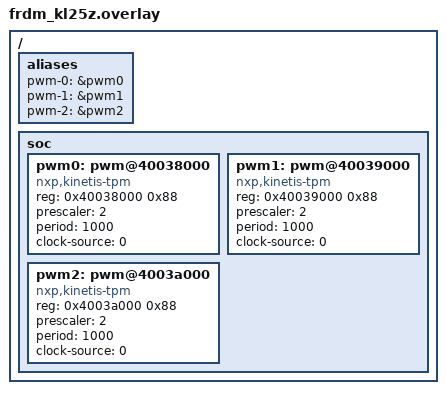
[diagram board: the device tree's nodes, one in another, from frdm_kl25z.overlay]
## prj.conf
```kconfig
CONFIG_STDOUT_CONSOLE=y
CONFIG_LOG=y
# CONFIG_SYS_CLOCK_TICKS_PER_SEC=250
#CONFIG_MICROBIT_DISPLAY_PIN_GRANULARITY=y

# PWM
# CONFIG_PWM=y
# CONFIG_PWM_0=y

# USB
# CONFIG_STDOUT_CONSOLE=y
# CONFIG_GPIO=y
# CONFIG_USB=y
# CONFIG_USB_DEVICE_STACK=y
# CONFIG_USB_DEVICE_BOS=y
# CONFIG_SERIAL=y
# CONFIG_USB_DEVICE_PRODUCT="Zephyr WebUSB sample"
# CONFIG_UART_INTERRUPT_DRIVEN=y
# CONFIG_UART_LINE_CTRL=y

# CONFIG_LOG=y
# CONFIG_USB_DRIVER_LOG_LEVEL_ERR=y
# CONFIG_USB_DEVICE_LOG_LEVEL_ERR=y

#CONFIG_USB_DEVICE_VID=
#CONFIG_USB_DEVICE_PID=

CONFIG_I2C=y
CONFIG_SENSOR=y
CONFIG_FXOS8700=y
CONFIG_SENSOR_LOG_LEVEL_DBG=y
# CONFIG_FXOS8700_MODE_HYBRID=y
# CONFIG_FXOS8700_TEMP=y
CONFIG_FXOS8700_TRIGGER_OWN_THREAD=y
```

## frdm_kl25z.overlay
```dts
/ {
	aliases {
		pwm-0 = &pwm0;
		pwm-1 = &pwm1;
		pwm-2 = &pwm2;
	};

	soc {
		pwm0: pwm@40038000 {
			compatible = "nxp,kinetis-tpm";
			reg = <0x40038000 0x88>;
			prescaler = <2>;
			period = <1000>;
			clock-source = <0>;
			/* channel information needed - fixme */
		};

		pwm1: pwm@40039000 {
			compatible = "nxp,kinetis-tpm";
			reg = <0x40039000 0x88>;
			prescaler = <2>;
			period = <1000>;
			clock-source = <0>;
			/* channel information needed - fixme */
		};

		pwm2: pwm@4003a000 {
			compatible = "nxp,kinetis-tpm";
			reg = <0x4003a000 0x88>;
			prescaler = <2>;
			period = <1000>;
			clock-source = <0>;
			/* channel information needed - fixme */
		};
	};
};
```

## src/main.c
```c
#include <zephyr.h>
#include <sensor.h>
#include <stdio.h>

#include "rgb_led.h"

K_SEM_DEFINE(sem, 0, 1);	/* starts off "not available" */

static void trigger_handler(struct device *dev, struct sensor_trigger *trigger)
{
	ARG_UNUSED(trigger);

	if (sensor_sample_fetch(dev)) {
		printf("sensor_sample_fetch failed\n");
		return;
	}

	k_sem_give(&sem);
}

void main(void)
{
	struct sensor_value accel[3];
	struct device *dev = device_get_binding(DT_NXP_FXOS8700_0_LABEL);

	if (dev == NULL) {
		printf("Could not get fxos8700 device\n");
		return;
	}

	struct sensor_value attr = {
		.val1 = 6,
		.val2 = 250000,
	};

	// if (val->val1 == 800 && val->val2 == 0) {
	// 	dr = FXOS8700_CTRLREG1_DR_RATE_800;
	// } else if (val->val1 == 400 && val->val2 == 0) {
	// 	dr = FXOS8700_CTRLREG1_DR_RATE_400;
	// } else if (val->val1 == 200 && val->val2 == 0) {
	// 	dr = FXOS8700_CTRLREG1_DR_RATE_200;
	// } else if (val->val1 == 100 && val->val2 == 0) {
	// 	dr = FXOS8700_CTRLREG1_DR_RATE_100;
	// } else if (val->val1 == 50 && val->val2 == 0) {
	// 	dr = FXOS8700_CTRLREG1_DR_RATE_50;
	// } else if (val->val1 == 12 && val->val2 == 500000) {
	// 	dr = FXOS8700_CTRLREG1_DR_RATE_12_5;
	// } else if (val->val1 == 6 && val->val2 == 250000) {
	// 	dr = FXOS8700_CTRLREG1_DR_RATE_6_25;
	// } else if (val->val1 == 1 && val->val2 == 562500) {
	// 	dr = FXOS8700_CTRLREG1_DR_RATE_1_56;
	// } else {
	// 	return -EINVAL;
	// }

	if (sensor_attr_set(dev, SENSOR_CHAN_ALL,
			    SENSOR_ATTR_SAMPLING_FREQUENCY, &attr)) {
		printk("Could not set sampling frequency\n");
		return;
	}

	struct sensor_trigger trig = {
		.type = SENSOR_TRIG_DATA_READY,
		.chan = SENSOR_CHAN_ACCEL_XYZ,
	};

	if (sensor_trigger_set(dev, &trig, trigger_handler)) {
		printf("Could not set trigger\n");
		return;
	}

	while (1) {
		k_sem_take(&sem, K_FOREVER);

		sensor_channel_get(dev, SENSOR_CHAN_ACCEL_XYZ, accel);
		printf("AX=%10.6f AY=%10.6f AZ=%10.6f ",
		       sensor_value_to_double(&accel[0]),
		       sensor_value_to_double(&accel[1]),
		       sensor_value_to_double(&accel[2]));
		printf("\n");
	}


	rgb_led_init();

	rgb_led_set(0xff,0,0); // Red to indicate 'starting up'
}
```

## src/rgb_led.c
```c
#include <zephyr.h>
#include <misc/printk.h>
#include <device.h>
#include <pwm.h>

#define PERIOD (USEC_PER_SEC / 100)

struct device *pwm_dev;

void rgb_led_init()
{
    // pwm_dev = device_get_binding(PWM_0_LABEL);

	// if (!pwm_dev) {
	// 	printk("Cannot find PWM device!\n");
	// 	return;
	// }
}

void rgb_led_set(u32_t r, u32_t g, u32_t b)
{
    // if( pwm_pin_set_usec(pwm_dev, PWM_0_CH0_PIN, PERIOD, ((255 - (r & 0xff)) * PERIOD) >> 8) != 0 ||
    //     pwm_pin_set_usec(pwm_dev, PWM_0_CH1_PIN, PERIOD, ((255 - (g & 0xff)) * PERIOD) >> 8) != 0 ||
    //     pwm_pin_set_usec(pwm_dev, PWM_0_CH2_PIN, PERIOD, ((255 - (b & 0xff)) * PERIOD) >> 8) != 0) {
    //     printk("PWM pin write fails!\n");
	// 	return;
    // }
}
```
